# PIC16LF777 register map
Vendor: Microchip
Registers are 8-bit, read-write, no defined reset value unless marked. A register's access mark holds for its fields unless they carry their own. Addresses are absolute, and some are shared; only a register's first bit layout is shown; [hi:lo] are bit positions; {n}, {i} and the like mark numbered series.

## SFR
0x00 INDF access not given
0x01 TMR0 — (power-on value xxxxxxxx)
0x02 PCL reset 0x0
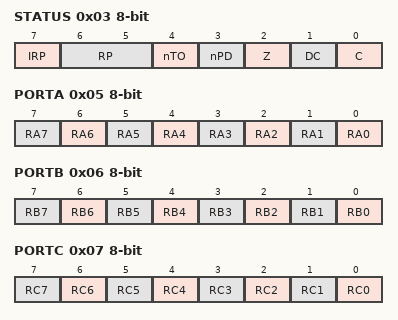
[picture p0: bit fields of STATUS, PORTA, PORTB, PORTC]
0x03 STATUS — (power-on value 00011xxx)
  [7] IRP, [6:5] RP, [4] nTO ro, [3] nPD ro, [2] Z, [1] DC, [0] C
0x04 FSR — (power-on value xxxxxxxx)
0x05 PORTA — (power-on value xx0x0000)
  [n] RA{n} (n=0..7)
0x06 PORTB — (power-on value xx000000)
  [n] RB{n} (n=0..7)
0x07 PORTC — (power-on value xxxxxxxx)
  [n] RC{n} (n=0..7)
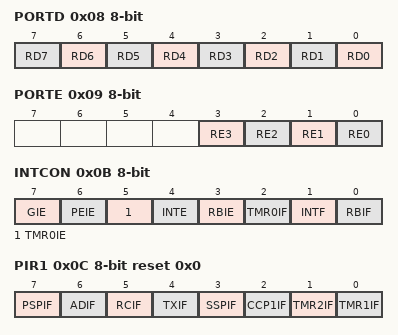
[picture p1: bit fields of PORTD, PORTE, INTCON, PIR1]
0x08 PORTD — (power-on value xxxxxxxx)
  [n] RD{n} (n=0..7)
0x09 PORTE — (power-on value ----x000)
  [3] RE3 ro, [2] RE2, [1] RE1, [0] RE0
0x0A PCLATH reset 0x0
  [4:0] PCLATH
0x0B INTCON — (power-on value 0000000x)
  [7] GIE, [6] PEIE, [5] TMR0IE, [4] INTE, [3] RBIE, [2] TMR0IF, [1] INTF, [0] RBIF
0x0C PIR1 reset 0x0
  [7] PSPIF, [6] ADIF, [5] RCIF ro, [4] TXIF ro, [3] SSPIF, [2] CCP1IF, [1] TMR2IF, [0] TMR1IF
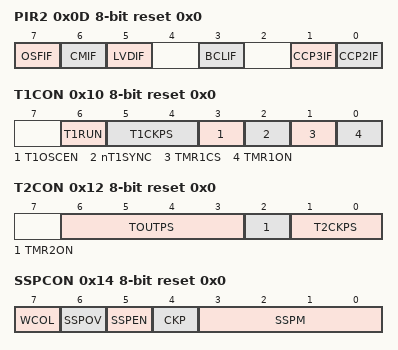
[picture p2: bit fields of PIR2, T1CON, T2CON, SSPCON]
0x0D PIR2 reset 0x0
  [7] OSFIF, [6] CMIF, [5] LVDIF, [3] BCLIF, [1] CCP3IF, [0] CCP2IF
0x0E TMR1L — (power-on value xxxxxxxx)
0x0F TMR1H — (power-on value xxxxxxxx)
0x10 T1CON reset 0x0
  [6] T1RUN, [5:4] T1CKPS, [3] T1OSCEN, [2] nT1SYNC, [1] TMR1CS, [0] TMR1ON
0x11 TMR2 reset 0x0
0x12 T2CON reset 0x0
  [6:3] TOUTPS, [2] TMR2ON, [1:0] T2CKPS
0x13 SSPBUF — (power-on value xxxxxxxx)
0x14 SSPCON reset 0x0
  [7] WCOL, [6] SSPOV, [5] SSPEN, [4] CKP, [3:0] SSPM
0x15 CCPR1L — (power-on value xxxxxxxx)
0x16 CCPR1H — (power-on value xxxxxxxx)
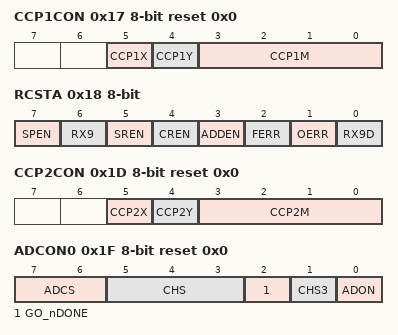
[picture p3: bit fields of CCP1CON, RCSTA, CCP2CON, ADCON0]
0x17 CCP1CON reset 0x0
  [5] CCP1X, [4] CCP1Y, [3:0] CCP1M
0x18 RCSTA — (power-on value 0000000x)
  [7] SPEN, [6] RX9, [5] SREN, [4] CREN, [3] ADDEN, [2] FERR ro, [1] OERR ro, [0] RX9D ro
0x19 TXREG reset 0x0
0x1A RCREG ro reset 0x0
0x1B CCPR2L — (power-on value xxxxxxxx)
0x1C CCPR2H — (power-on value xxxxxxxx)
0x1D CCP2CON reset 0x0
  [5] CCP2X, [4] CCP2Y, [3:0] CCP2M
0x1E ADRESH — (power-on value xxxxxxxx)
0x1F ADCON0 reset 0x0
  [7:6] ADCS, [5:3] CHS, [2] GO_nDONE, [1] CHS3, [0] ADON
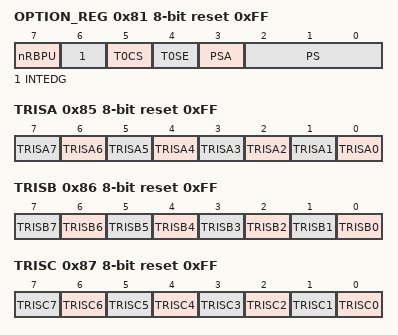
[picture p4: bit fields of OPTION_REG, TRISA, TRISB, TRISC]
0x81 OPTION_REG reset 0xFF
  [7] nRBPU, [6] INTEDG, [5] T0CS, [4] T0SE, [3] PSA, [2:0] PS
0x85 TRISA reset 0xFF
  [n] TRISA{n} (n=0..7)
0x86 TRISB reset 0xFF
  [n] TRISB{n} (n=0..7)
0x87 TRISC reset 0xFF
  [n] TRISC{n} (n=0..7)
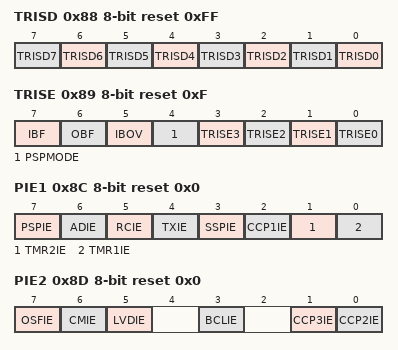
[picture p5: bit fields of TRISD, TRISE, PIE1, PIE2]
0x88 TRISD reset 0xFF
  [n] TRISD{n} (n=0..7)
0x89 TRISE reset 0xF
  [7] IBF ro, [6] OBF ro, [5] IBOV, [4] PSPMODE, [3] TRISE3 ro, [2] TRISE2, [1] TRISE1, [0] TRISE0
0x8C PIE1 reset 0x0
  [7] PSPIE, [6] ADIE, [5] RCIE, [4] TXIE, [3] SSPIE, [2] CCP1IE, [1] TMR2IE, [0] TMR1IE
0x8D PIE2 reset 0x0
  [7] OSFIE, [6] CMIE, [5] LVDIE, [3] BCLIE, [1] CCP3IE, [0] CCP2IE
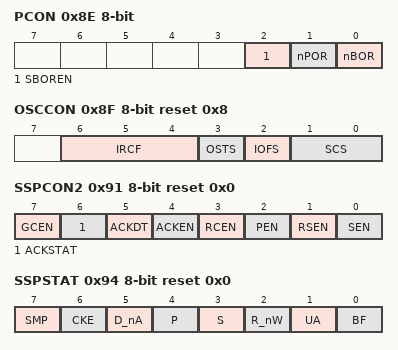
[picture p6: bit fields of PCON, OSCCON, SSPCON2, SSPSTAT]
0x8E PCON — (power-on value -----1qq)
  [2] SBOREN, [1] nPOR, [0] nBOR
0x8F OSCCON reset 0x8
  [6:4] IRCF, [3] OSTS ro, [2] IOFS ro, [1:0] SCS
0x90 OSCTUNE reset 0x0
  [5:0] TUN
0x91 SSPCON2 reset 0x0
  [7] GCEN, [6] ACKSTAT, [5] ACKDT, [4] ACKEN, [3] RCEN, [2] PEN, [1] RSEN, [0] SEN
0x92 PR2 reset 0xFF
0x93 SSPADD reset 0x0
0x94 SSPSTAT reset 0x0
  [7] SMP, [6] CKE, [5] D_nA, [4] P, [3] S, [2] R_nW, [1] UA, [0] BF
0x95 CCPR3L — (power-on value xxxxxxxx)
0x96 CCPR3H — (power-on value xxxxxxxx)
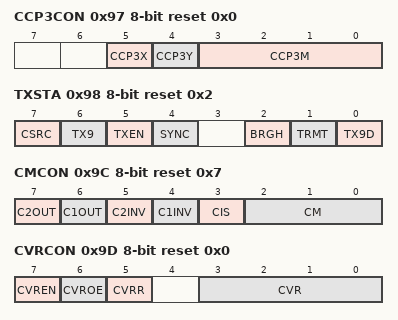
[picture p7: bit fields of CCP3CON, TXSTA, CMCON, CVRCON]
0x97 CCP3CON reset 0x0
  [5] CCP3X, [4] CCP3Y, [3:0] CCP3M
0x98 TXSTA reset 0x2
  [7] CSRC, [6] TX9, [5] TXEN, [4] SYNC, [2] BRGH, [1] TRMT ro, [0] TX9D
0x99 SPBRG reset 0x0
0x9B ADCON2 reset 0x0
  [5:3] ACQT
0x9C CMCON reset 0x7
  [7] C2OUT ro, [6] C1OUT ro, [5] C2INV, [4] C1INV, [3] CIS, [2:0] CM
0x9D CVRCON reset 0x0
  [7] CVREN, [6] CVROE, [5] CVRR, [3:0] CVR
0x9E ADRESL — (power-on value xxxxxxxx)
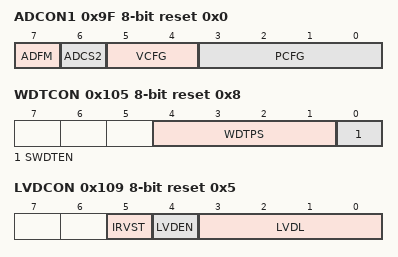
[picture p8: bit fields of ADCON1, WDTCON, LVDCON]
0x9F ADCON1 reset 0x0
  [7] ADFM, [6] ADCS2, [5:4] VCFG, [3:0] PCFG
0x105 WDTCON reset 0x8
  [4:1] WDTPS, [0] SWDTEN
0x109 LVDCON reset 0x5
  [5] IRVST, [4] LVDEN, [3:0] LVDL
0x10C PMDATA — (power-on value xxxxxxxx)
0x10D PMADR — (power-on value xxxxxxxx)
0x10E PMDATH — (power-on value --xxxxxx)
  [5:0] PMDATH
0x10F PMADRH — (power-on value ---xxxxx)
  [4:0] PMADRH
0x18C PMCON1 reset 0x0
  [0] RD — (can only be set)
